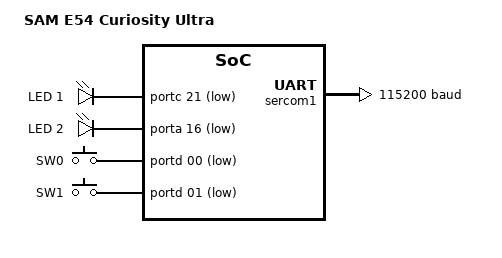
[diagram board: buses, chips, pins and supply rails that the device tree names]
/*
 * Copyright (c) 2025 Microchip Technology Inc.
 *
 * SPDX-License-Identifier: Apache-2.0
 */

/dts-v1/;
#include <microchip/sam/sam_d5x_e5x/atsame54/atsame54p20a.dtsi>
#include "sam_e54_cult-pinctrl.dtsi"
#include <zephyr/dt-bindings/input/input-event-codes.h>

/ {
	model = "SAM E54 Curiosity Ultra";
	compatible = "microchip,sam_e54_cult";

	chosen {
		zephyr,console = &sercom1;
		zephyr,shell-uart = &sercom1;
		zephyr,sram = &sram0;
		zephyr,flash = &flash0;
		zephyr,code-partition = &slot0_partition;
		zephyr,flash-controller = &nvmctrl;
	};

	aliases {
		led0 = &led1;
		sw0 = &button0;
	};

	leds {
		compatible = "gpio-leds";

		led1: led_1 {
			gpios = <&portc 21 GPIO_ACTIVE_LOW>;
			label = "LED 1";
		};

		led2: led_2 {
			gpios = <&porta 16 GPIO_ACTIVE_LOW>;
			label = "LED 2";
		};
	};

	buttons {
		compatible = "gpio-keys";

		button0: button_0 {
			gpios = <&portd 00 (GPIO_PULL_UP | GPIO_ACTIVE_LOW)>;
			label = "SW0";
			zephyr,code = <INPUT_KEY_0>;
		};

		button1: button_1 {
			gpios = <&portd 01 (GPIO_PULL_UP | GPIO_ACTIVE_LOW)>;
			label = "SW1";
			zephyr,code = <INPUT_KEY_1>;
		};
	};
};

&flash0 {
	partitions {
		compatible = "fixed-partitions";
		#address-cells = <1>;
		#size-cells = <1>;

		boot_partition: partition@0 {
			reg = <0x00000000 0x00010000>;  /* 64 KB bootloader */
			read-only;
		};

		slot0_partition: partition@10000 {
			reg = <0x00010000 0x00070000>;  /* 448 KB primary app slot */
		};

		slot1_partition: partition@80000 {
			reg = <0x00080000 0x00070000>;  /* 448 KB secondary app slot */
		};

		storage_partition: partition@f0000 {
			reg = <0x000f0000 0x00010000>;  /* 64 KB storage area */
		};
	};
};

&cpu0 {
	clock-frequency = <48000000>;
};

&sercom1 {
	compatible = "microchip,sercom-g1-uart";
	#address-cells = <1>;
	#size-cells = <0>;

	current-speed = <115200>;
	data-bits = <8>;
	parity = "none";
	stop-bits = "1";

	rxpo = <1>;
	txpo = <0>;

	pinctrl-0 = <&sercom1_uart_default>;
	pinctrl-names = "default";
	status = "okay";
};

&porta {
	status = "okay";
};

&portc {
	status = "okay";
};

&portd {
	status = "okay";
};
